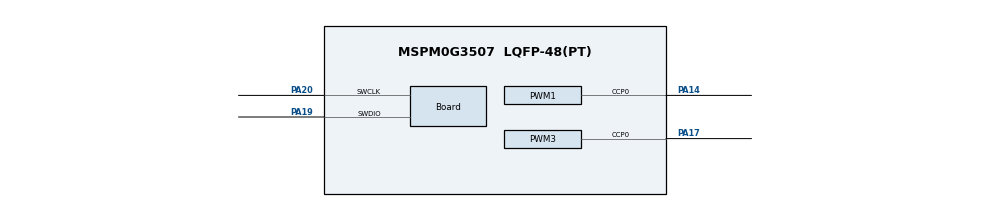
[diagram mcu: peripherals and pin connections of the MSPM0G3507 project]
/**
 * These arguments were used when this file was generated. They will be automatically applied on subsequent loads
 * via the GUI or CLI. Run CLI with '--help' for additional information on how to override these arguments.
 * @cliArgs --device "MSPM0G350X" --part "Default" --package "LQFP-48(PT)" --product "mspm0_sdk@2.04.00.06"
 * @v2CliArgs --device "MSPM0G3507" --package "LQFP-48(PT)" --product "mspm0_sdk@2.04.00.06"
 * @versions {"tool":"1.22.0+3893"}
 */

/**
 * Import the modules used in this configuration.
 */
const Board         = scripting.addModule("/ti/driverlib/Board");
const GPIO          = scripting.addModule("/ti/driverlib/GPIO", {}, false);
const GPIO1         = GPIO.addInstance();
const GPIO2         = GPIO.addInstance();
const GPIO3         = GPIO.addInstance();
const GPIO4         = GPIO.addInstance();
const GPIO5         = GPIO.addInstance();
const GPIO6         = GPIO.addInstance();
const MATHACL       = scripting.addModule("/ti/driverlib/MATHACL");
const PWM           = scripting.addModule("/ti/driverlib/PWM", {}, false);
const PWM1          = PWM.addInstance();
const PWM2          = PWM.addInstance();
const PWM3          = PWM.addInstance();
const SYSCTL        = scripting.addModule("/ti/driverlib/SYSCTL");
const SYSTICK       = scripting.addModule("/ti/driverlib/SYSTICK");
const TIMER         = scripting.addModule("/ti/driverlib/TIMER", {}, false);
const TIMER1        = TIMER.addInstance();
const TIMER2        = TIMER.addInstance();
const UART          = scripting.addModule("/ti/driverlib/UART", {}, false);
const UART1         = UART.addInstance();
const ProjectConfig = scripting.addModule("/ti/project_config/ProjectConfig");

/**
 * Write custom configuration values to the imported modules.
 */
const gate7  = system.clockTree["MFCLKGATE"];
gate7.enable = true;

Board.InitPriority0               = "/ti/driverlib/MCAN";
Board.peripheral.$assign          = "DEBUGSS";
Board.peripheral.swclkPin.$assign = "PA20";
Board.peripheral.swdioPin.$assign = "PA19";

GPIO1.$name                              = "BSL";
GPIO1.associatedPins[0].$name            = "PIN_18";
GPIO1.associatedPins[0].assignedPin      = "18";
GPIO1.associatedPins[0].assignedPort     = "PORTA";
GPIO1.associatedPins[0].internalResistor = "PULL_DOWN";

GPIO2.$name                              = "I2C";
GPIO2.associatedPins.create(2);
GPIO2.associatedPins[0].$name            = "SDA";
GPIO2.associatedPins[0].assignedPin      = "28";
GPIO2.associatedPins[0].initialValue     = "SET";
GPIO2.associatedPins[1].$name            = "SCL";
GPIO2.associatedPins[1].internalResistor = "PULL_UP";
GPIO2.associatedPins[1].assignedPort     = "PORTA";
GPIO2.associatedPins[1].assignedPin      = "31";
GPIO2.associatedPins[1].initialValue     = "SET";

GPIO3.$name                          = "TB6612";
GPIO3.associatedPins.create(5);
GPIO3.associatedPins[0].$name        = "STBY";
GPIO3.associatedPins[0].initialValue = "SET";
GPIO3.associatedPins[0].assignedPort = "PORTA";
GPIO3.associatedPins[0].assignedPin  = "12";
GPIO3.associatedPins[1].$name        = "AIN1";
GPIO3.associatedPins[1].initialValue = "SET";
GPIO3.associatedPins[1].assignedPort = "PORTB";
GPIO3.associatedPins[1].assignedPin  = "6";
GPIO3.associatedPins[2].$name        = "AIN2";
GPIO3.associatedPins[2].initialValue = "SET";
GPIO3.associatedPins[2].assignedPin  = "7";
GPIO3.associatedPins[2].assignedPort = "PORTB";
GPIO3.associatedPins[3].$name        = "BIN1";
GPIO3.associatedPins[3].initialValue = "SET";
GPIO3.associatedPins[3].assignedPin  = "8";
GPIO3.associatedPins[3].assignedPort = "PORTA";
GPIO3.associatedPins[4].$name        = "BIN2";
GPIO3.associatedPins[4].initialValue = "SET";
GPIO3.associatedPins[4].assignedPin  = "9";
GPIO3.associatedPins[4].assignedPort = "PORTA";

GPIO4.port                                = "PORTB";
GPIO4.$name                               = "GPIO_Encoder_L";
GPIO4.associatedPins.create(2);
GPIO4.associatedPins[0].direction         = "INPUT";
GPIO4.associatedPins[0].interruptEn       = true;
GPIO4.associatedPins[0].internalResistor  = "PULL_UP";
GPIO4.associatedPins[0].interruptPriority = "1";
GPIO4.associatedPins[0].inputFilter       = "8_CYCLES";
GPIO4.associatedPins[0].polarity          = "RISE";
GPIO4.associatedPins[0].assignedPin       = "24";
GPIO4.associatedPins[0].$name             = "L_A";
GPIO4.associatedPins[1].direction         = "INPUT";
GPIO4.associatedPins[1].interruptEn       = true;
GPIO4.associatedPins[1].internalResistor  = "PULL_UP";
GPIO4.associatedPins[1].interruptPriority = "1";
GPIO4.associatedPins[1].polarity          = "RISE";
GPIO4.associatedPins[1].inputFilter       = "8_CYCLES";
GPIO4.associatedPins[1].assignedPin       = "20";
GPIO4.associatedPins[1].$name             = "L_B";

GPIO5.port                                = "PORTA";
GPIO5.$name                               = "GPIO_Encoder_R";
GPIO5.associatedPins.create(2);
GPIO5.associatedPins[0].direction         = "INPUT";
GPIO5.associatedPins[0].internalResistor  = "PULL_DOWN";
GPIO5.associatedPins[0].inputFilter       = "8_CYCLES";
GPIO5.associatedPins[0].polarity          = "RISE";
GPIO5.associatedPins[0].interruptEn       = true;
GPIO5.associatedPins[0].interruptPriority = "1";
GPIO5.associatedPins[0].assignedPin       = "16";
GPIO5.associatedPins[0].$name             = "R_B";
GPIO5.associatedPins[1].direction         = "INPUT";
GPIO5.associatedPins[1].assignedPin       = "15";
GPIO5.associatedPins[1].internalResistor  = "PULL_UP";
GPIO5.associatedPins[1].inputFilter       = "8_CYCLES";
GPIO5.associatedPins[1].polarity          = "RISE";
GPIO5.associatedPins[1].interruptEn       = true;
GPIO5.associatedPins[1].$name             = "R_A";

GPIO6.$name                              = "Tracking";
GPIO6.associatedPins.create(5);
GPIO6.associatedPins[0].direction        = "INPUT";
GPIO6.associatedPins[0].$name            = "HW_5";
GPIO6.associatedPins[0].assignedPort     = "PORTA";
GPIO6.associatedPins[0].assignedPin      = "27";
GPIO6.associatedPins[0].internalResistor = "PULL_DOWN";
GPIO6.associatedPins[1].$name            = "HW_4";
GPIO6.associatedPins[1].direction        = "INPUT";
GPIO6.associatedPins[1].assignedPort     = "PORTA";
GPIO6.associatedPins[1].assignedPin      = "26";
GPIO6.associatedPins[1].internalResistor = "PULL_DOWN";
GPIO6.associatedPins[2].$name            = "HW_3";
GPIO6.associatedPins[2].direction        = "INPUT";
GPIO6.associatedPins[2].assignedPort     = "PORTA";
GPIO6.associatedPins[2].assignedPin      = "25";
GPIO6.associatedPins[2].internalResistor = "PULL_DOWN";
GPIO6.associatedPins[3].$name            = "HW_2";
GPIO6.associatedPins[3].direction        = "INPUT";
GPIO6.associatedPins[3].assignedPort     = "PORTA";
GPIO6.associatedPins[3].assignedPin      = "24";
GPIO6.associatedPins[3].internalResistor = "PULL_DOWN";
GPIO6.associatedPins[4].$name            = "HW_1";
GPIO6.associatedPins[4].direction        = "INPUT";
GPIO6.associatedPins[4].assignedPort     = "PORTA";
GPIO6.associatedPins[4].assignedPin      = "23";
GPIO6.associatedPins[4].internalResistor = "PULL_DOWN";

PWM1.$name                              = "PWM_R";
PWM1.timerStartTimer                    = true;
PWM1.ccIndex                            = [0];
PWM1.pwmMode                            = "EDGE_ALIGN_UP";
PWM1.clockDivider                       = 8;
PWM1.peripheral.$assign                 = "TIMG12";
PWM1.peripheral.ccp0Pin.$assign         = "PA14";
PWM1.PWM_CHANNEL_0.$name                = "ti_driverlib_pwm_PWMTimerCC0";
PWM1.ccp0PinConfig.$name                = "ti_driverlib_gpio_GPIOPinGeneric0";
PWM1.ccp0PinConfig.direction            = scripting.forceWrite("OUTPUT");
PWM1.ccp0PinConfig.hideOutputInversion  = scripting.forceWrite(false);
PWM1.ccp0PinConfig.onlyInternalResistor = scripting.forceWrite(false);
PWM1.ccp0PinConfig.passedPeripheralType = scripting.forceWrite("Digital");
PWM1.ccp0PinConfig.enableConfig         = true;
PWM1.ccp0PinConfig.internalResistor     = "PULL_UP";

PWM2.$name                              = "PWM_L";
PWM2.timerStartTimer                    = true;
PWM2.ccIndex                            = [1];
PWM2.clockDivider                       = 8;
PWM2.pwmMode                            = "EDGE_ALIGN_UP";
PWM2.peripheral.$assign                 = "TIMG0";
PWM2.ccp1PinConfig.direction            = scripting.forceWrite("OUTPUT");
PWM2.ccp1PinConfig.hideOutputInversion  = scripting.forceWrite(false);
PWM2.ccp1PinConfig.onlyInternalResistor = scripting.forceWrite(false);
PWM2.ccp1PinConfig.passedPeripheralType = scripting.forceWrite("Digital");
PWM2.ccp1PinConfig.$name                = "ti_driverlib_gpio_GPIOPinGeneric1";
PWM2.ccp1PinConfig.enableConfig         = true;
PWM2.ccp1PinConfig.internalResistor     = "PULL_UP";
PWM2.PWM_CHANNEL_1.$name                = "ti_driverlib_pwm_PWMTimerCC1";

PWM3.$name                              = "PWM_Buzzer";
PWM3.clockSource                        = "MFCLK";
PWM3.timerStartTimer                    = true;
PWM3.pwmMode                            = "EDGE_ALIGN_UP";
PWM3.ccIndex                            = [0];
PWM3.peripheral.ccp0Pin.$assign         = "PA17";
PWM3.PWM_CHANNEL_0.$name                = "ti_driverlib_pwm_PWMTimerCC2";
PWM3.ccp0PinConfig.$name                = "ti_driverlib_gpio_GPIOPinGeneric4";
PWM3.ccp0PinConfig.direction            = scripting.forceWrite("OUTPUT");
PWM3.ccp0PinConfig.hideOutputInversion  = scripting.forceWrite(false);
PWM3.ccp0PinConfig.onlyInternalResistor = scripting.forceWrite(false);
PWM3.ccp0PinConfig.passedPeripheralType = scripting.forceWrite("Digital");

SYSCTL.forceDefaultClkConfig = true;
SYSCTL.clockTreeEn           = true;

SYSTICK.periodEnable      = true;
SYSTICK.interruptEnable   = true;
SYSTICK.systickEnable     = true;
SYSTICK.period            = 32000;
SYSTICK.interruptPriority = "0";

TIMER1.timerClkPrescale   = 100;
TIMER1.timerPeriod        = "20 ms";
TIMER1.timerStartTimer    = true;
TIMER1.timerMode          = "PERIODIC";
TIMER1.interrupts         = ["ZERO"];
TIMER1.interruptPriority  = "1";
TIMER1.$name              = "TIMER_Encoder_Read";
TIMER1.peripheral.$assign = "TIMG6";

TIMER2.$name             = "TIMER_Tracking_Read";
TIMER2.timerClkPrescale  = 4;
TIMER2.timerPeriod       = "5 ms";
TIMER2.timerStartTimer   = true;
TIMER2.interrupts        = ["ZERO"];
TIMER2.interruptPriority = "1";
TIMER2.timerMode         = "PERIODIC";

UART1.$name                            = "HC_06";
UART1.enabledInterrupts                = ["RX"];
UART1.interruptPriority                = "1";
UART1.peripheral.$assign               = "UART2";
UART1.txPinConfig.direction            = scripting.forceWrite("OUTPUT");
UART1.txPinConfig.hideOutputInversion  = scripting.forceWrite(false);
UART1.txPinConfig.onlyInternalResistor = scripting.forceWrite(false);
UART1.txPinConfig.passedPeripheralType = scripting.forceWrite("Digital");
UART1.txPinConfig.$name                = "ti_driverlib_gpio_GPIOPinGeneric2";
UART1.rxPinConfig.hideOutputInversion  = scripting.forceWrite(false);
UART1.rxPinConfig.onlyInternalResistor = scripting.forceWrite(false);
UART1.rxPinConfig.passedPeripheralType = scripting.forceWrite("Digital");
UART1.rxPinConfig.$name                = "ti_driverlib_gpio_GPIOPinGeneric3";

ProjectConfig.migrationCondition = true;
ProjectConfig.genLibIQ           = true;
ProjectConfig.genLibIQVersion    = "MATHACL";

/**
 * Pinmux solution for unlocked pins/peripherals. This ensures that minor changes to the automatic solver in a future
 * version of the tool will not impact the pinmux you originally saw.  These lines can be completely deleted in order to
 * re-solve from scratch.
 */
GPIO1.associatedPins[0].pin.$suggestSolution = "PA18";
GPIO2.associatedPins[0].pin.$suggestSolution = "PA28";
GPIO2.associatedPins[1].pin.$suggestSolution = "PA31";
GPIO3.associatedPins[0].pin.$suggestSolution = "PA12";
GPIO3.associatedPins[1].pin.$suggestSolution = "PB6";
GPIO3.associatedPins[2].pin.$suggestSolution = "PB7";
GPIO3.associatedPins[3].pin.$suggestSolution = "PA8";
GPIO3.associatedPins[4].pin.$suggestSolution = "PA9";
GPIO4.associatedPins[0].pin.$suggestSolution = "PB24";
GPIO4.associatedPins[1].pin.$suggestSolution = "PB20";
GPIO5.associatedPins[0].pin.$suggestSolution = "PA16";
GPIO5.associatedPins[1].pin.$suggestSolution = "PA15";
GPIO6.associatedPins[0].pin.$suggestSolution = "PA27";
GPIO6.associatedPins[1].pin.$suggestSolution = "PA26";
GPIO6.associatedPins[2].pin.$suggestSolution = "PA25";
GPIO6.associatedPins[3].pin.$suggestSolution = "PA24";
GPIO6.associatedPins[4].pin.$suggestSolution = "PA23";
PWM2.peripheral.ccp1Pin.$suggestSolution     = "PA13";
PWM3.peripheral.$suggestSolution             = "TIMA1";
TIMER2.peripheral.$suggestSolution           = "TIMA0";
UART1.peripheral.rxPin.$suggestSolution      = "PA22";
UART1.peripheral.txPin.$suggestSolution      = "PA21";
